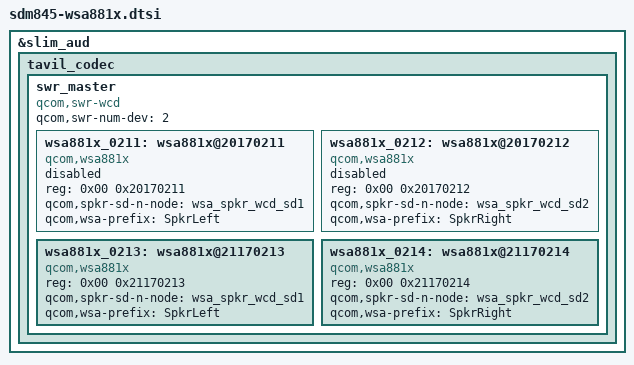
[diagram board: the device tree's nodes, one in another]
// SPDX-License-Identifier: GPL-2.0-only
/*
 * Copyright (c) 2016-2017, The Linux Foundation. All rights reserved.
 * Copyright (c) 2021-2022, 2025, Pavel Dubrova <pashadubrova@gmail.com>
 */

&slim_aud {
	tavil_codec {
		swr_master {
			compatible = "qcom,swr-wcd";
			qcom,swr-num-dev = <2>;
			#address-cells = <2>;
			#size-cells = <0>;

			/* Disable WSA8810 by default */
			wsa881x_0211: wsa881x@20170211 {
				compatible = "qcom,wsa881x";
				reg = <0x00 0x20170211>;
				qcom,spkr-sd-n-node = <&wsa_spkr_wcd_sd1>;
				qcom,wsa-prefix = "SpkrLeft";
				status = "disabled";
			};

			wsa881x_0212: wsa881x@20170212 {
				compatible = "qcom,wsa881x";
				reg = <0x00 0x20170212>;
				qcom,spkr-sd-n-node = <&wsa_spkr_wcd_sd2>;
				qcom,wsa-prefix = "SpkrRight";
				status = "disabled";
			};

			wsa881x_0213: wsa881x@21170213 {
				compatible = "qcom,wsa881x";
				reg = <0x00 0x21170213>;
				qcom,spkr-sd-n-node = <&wsa_spkr_wcd_sd1>;
				qcom,wsa-prefix = "SpkrLeft";
			};

			wsa881x_0214: wsa881x@21170214 {
				compatible = "qcom,wsa881x";
				reg = <0x00 0x21170214>;
				qcom,spkr-sd-n-node = <&wsa_spkr_wcd_sd2>;
				qcom,wsa-prefix = "SpkrRight";
			};
		};
	};
};
